VERSION ""

NS_ :

BS_:

BU_: Pegasus Marvel Laptop Stark Xavier stark Pegasus Marvel Laptop Stark Xavier stark Gtake

BO_ 1542 id606: 8 Stark
 SG_ Aux_battery_voltage : 15|16@0+ (0.01,0) [0|655.35] "V" Vector__XXX

BO_ 1801 id709: 8 Pegasus
 SG_ Fault_historic_details : 0|64@1+ (1,0) [0|255] "" Vector__XXX

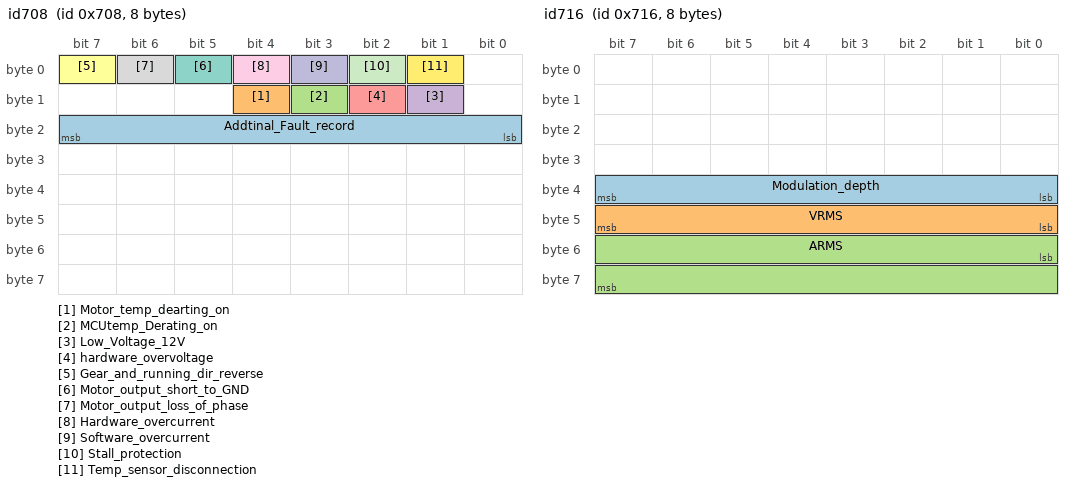
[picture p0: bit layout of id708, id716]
BO_ 1800 id708: 8 Pegasus
 SG_ Addtinal_Fault_record : 16|8@1+ (1,0) [0|255] "" Vector__XXX
 SG_ Motor_temp_dearting_on : 12|1@1+ (1,0) [0|1] "" Vector__XXX
 SG_ MCUtemp_Derating_on : 11|1@1+ (1,0) [0|1] "" Vector__XXX
 SG_ Low_Voltage_12V : 9|1@1+ (1,0) [0|1] "" Vector__XXX
 SG_ hardware_overvoltage : 10|1@1+ (1,0) [0|1] "" Vector__XXX
 SG_ Gear_and_running_dir_reverse : 7|1@1+ (1,0) [0|1] "" Vector__XXX
 SG_ Motor_output_short_to_GND : 5|1@1+ (1,0) [0|1] "" Vector__XXX
 SG_ Motor_output_loss_of_phase : 6|1@1+ (1,0) [0|1] "" Vector__XXX
 SG_ Hardware_overcurrent : 4|1@1+ (1,0) [0|1] "" Vector__XXX
 SG_ Software_overcurrent : 3|1@1+ (1,0) [0|1] "" Vector__XXX
 SG_ Stall_protection : 2|1@1+ (1,0) [0|1] "" Vector__XXX
 SG_ Temp_sensor_disconnection : 1|1@1+ (1,0) [0|1] "" Vector__XXX

BO_ 1828 id724: 8 Pegasus
 SG_ Motor_Torque_Estimated : 0|16@1- (0.1,0) [-3276.8|3276.7] "Nm" Vector__XXX

BO_ 1815 id717: 8 Pegasus
 SG_ Operating_frequency : 0|16@1- (1,0) [-32768|32767] "Hz" Vector__XXX

BO_ 1814 id716: 8 Pegasus
 SG_ Modulation_depth : 32|8@1+ (1,0) [0|0] "%" Vector__XXX
 SG_ VRMS : 40|8@1+ (1,0) [0|255] "V rms" Vector__XXX
 SG_ ARMS : 48|16@1+ (1,0) [0|65535] "A rms" Vector__XXX

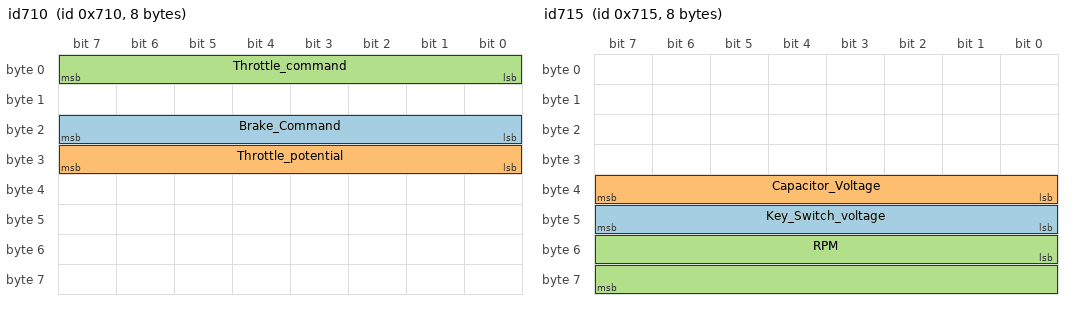
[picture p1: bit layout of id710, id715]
BO_ 1808 id710: 8 Pegasus
 SG_ Brake_Command : 16|8@1+ (1,0) [0|1] "" Vector__XXX
 SG_ Throttle_potential : 24|8@1+ (0.1,0) [0|25.5] "V" Vector__XXX
 SG_ Throttle_command : 0|8@1+ (1,0) [0|255] "%" Vector__XXX

BO_ 1813 id715: 8 Pegasus
 SG_ Key_Switch_voltage : 40|8@1+ (1,0) [0|24] "V" Vector__XXX
 SG_ Capacitor_Voltage : 32|8@1+ (1,0) [0|255] "V" Vector__XXX
 SG_ RPM : 48|16@1+ (1,0) [0|65535] "RPM" Vector__XXX

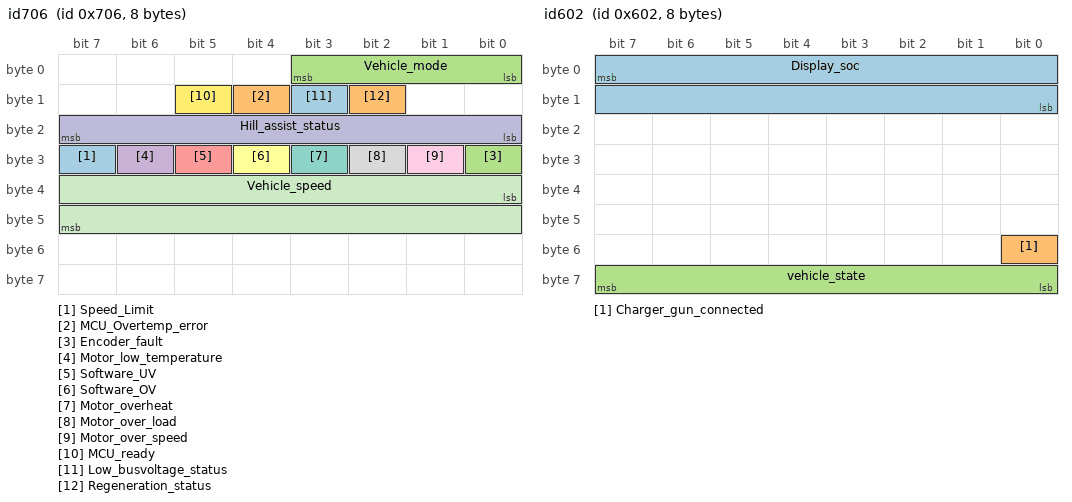
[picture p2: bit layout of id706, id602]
BO_ 1798 id706: 8 Pegasus
 SG_ Speed_Limit : 31|1@1+ (1,0) [0|1] "" Vector__XXX
 SG_ MCU_Overtemp_error : 12|1@1+ (1,0) [0|1] "" Vector__XXX
 SG_ Encoder_fault : 24|1@1+ (1,0) [0|1] "" Vector__XXX
 SG_ Motor_low_temperature : 30|1@1+ (1,0) [0|1] "" Vector__XXX
 SG_ Software_UV : 29|1@1+ (1,0) [0|1] "" Vector__XXX
 SG_ Software_OV : 28|1@1+ (1,0) [0|1] "" Vector__XXX
 SG_ Motor_overheat : 27|1@1+ (1,0) [0|1] "" Vector__XXX
 SG_ Motor_over_load : 26|1@1+ (1,0) [0|1] "" Vector__XXX
 SG_ Motor_over_speed : 25|1@1+ (1,0) [0|0] "" Vector__XXX
 SG_ Hill_assist_status : 16|8@1+ (1,0) [0|255] "" Vector__XXX
 SG_ Vehicle_speed : 32|16@1- (0.1,0) [-3276.8|3276.7] "Kmph" Vector__XXX
 SG_ MCU_ready : 13|1@1+ (1,0) [0|1] "" Vector__XXX
 SG_ Low_busvoltage_status : 11|1@1+ (1,0) [0|0] "" Vector__XXX
 SG_ Regeneration_status : 10|1@1+ (1,0) [0|1] "" Vector__XXX
 SG_ Vehicle_mode : 0|4@1+ (1,0) [0|15] "" Vector__XXX

BO_ 1797 id705: 8 Pegasus
 SG_ MCU_Temperature : 8|8@1+ (1,-50) [0|255] "C" Vector__XXX
 SG_ Motor_Temperature : 0|8@1+ (1,-50) [0|255] "C" Vector__XXX

BO_ 1025 id401: 8 Xavier
 SG_ Display_Speed : 0|8@1+ (1,0) [0|255] "Kmph" Vector__XXX

BO_ 1538 id602: 8 Stark
 SG_ Display_soc : 7|16@0+ (0.1,0) [0|0] "%" Vector__XXX
 SG_ Charger_gun_connected : 48|1@1+ (1,0) [0|2] "" Vector__XXX
 SG_ vehicle_state : 63|8@0+ (1,0) [0|10] "" Vector__XXX

BO_ 1539 id603: 8 Stark
 SG_ Odometer : 23|32@0+ (0.01,0) [0|429496729.5] "Km" Vector__XXX

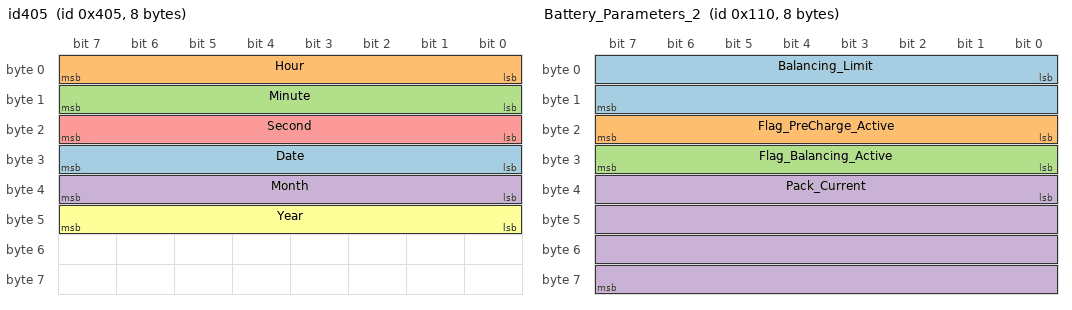
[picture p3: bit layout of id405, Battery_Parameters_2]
BO_ 1029 id405: 8 Xavier
 SG_ Date : 24|8@1+ (1,0) [0|0] "" Vector__XXX
 SG_ Hour : 0|8@1+ (1,0) [0|0] "" Vector__XXX
 SG_ Minute : 8|8@1+ (1,0) [0|0] "" Vector__XXX
 SG_ Month : 32|8@1+ (1,0) [0|0] "" Vector__XXX
 SG_ Second : 16|8@1+ (1,0) [0|0] "" Vector__XXX
 SG_ Year : 40|8@1+ (1,0) [0|0] "" Vector__XXX

BO_ 272 Battery_Parameters_2: 8 Vector__XXX
 SG_ Balancing_Limit : 0|16@1+ (0.1,0) [0|6553.5] "mV" Vector__XXX
 SG_ Flag_PreCharge_Active : 16|8@1+ (1,0) [0|255] "" Vector__XXX
 SG_ Flag_Balancing_Active : 24|8@1+ (1,0) [0|255] "" Vector__XXX
 SG_ Pack_Current : 32|32@1- (1E-05,0) [-21474.8|21474.8] "A" Vector__XXX

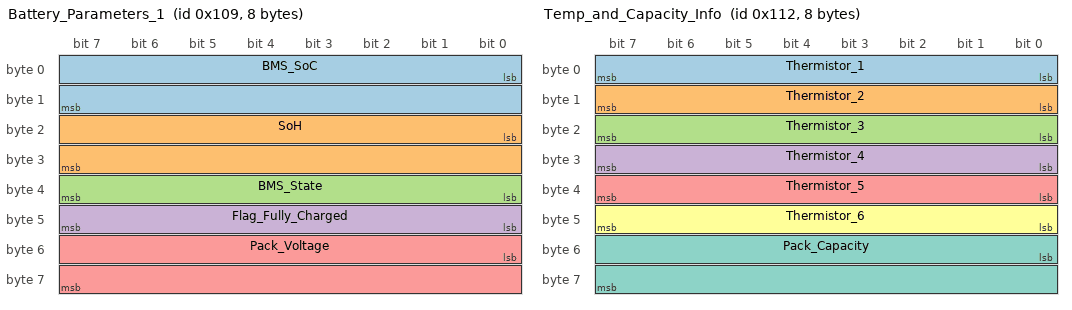
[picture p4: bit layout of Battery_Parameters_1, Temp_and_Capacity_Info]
BO_ 265 Battery_Parameters_1: 8 Vector__XXX
 SG_ BMS_SoC : 0|16@1+ (0.01,0) [0|655.35] "%" Vector__XXX
 SG_ SoH : 16|16@1+ (0.01,0) [0|655.35] "%" Vector__XXX
 SG_ BMS_State : 32|8@1+ (1,0) [0|255] "" Vector__XXX
 SG_ Flag_Fully_Charged : 40|8@1+ (1,0) [0|255] "" Vector__XXX
 SG_ Pack_Voltage : 48|16@1+ (0.1,0) [0|6553.5] "V" Vector__XXX

BO_ 274 Temp_and_Capacity_Info: 8 Vector__XXX
 SG_ Thermistor_1 : 0|8@1- (1,0) [-128|127] "degC" Vector__XXX
 SG_ Thermistor_2 : 8|8@1- (1,0) [-128|127] "degC" Vector__XXX
 SG_ Thermistor_3 : 16|8@1- (1,0) [-128|127] "degC" Vector__XXX
 SG_ Thermistor_4 : 24|8@1- (1,0) [-128|127] "degC" Vector__XXX
 SG_ Thermistor_5 : 32|8@1- (1,0) [-128|127] "degC" Vector__XXX
 SG_ Thermistor_6 : 40|8@1- (1,0) [-128|127] "degC" Vector__XXX
 SG_ Pack_Capacity : 48|16@1+ (0.01,0) [0|6553.5] "Ah" Vector__XXX

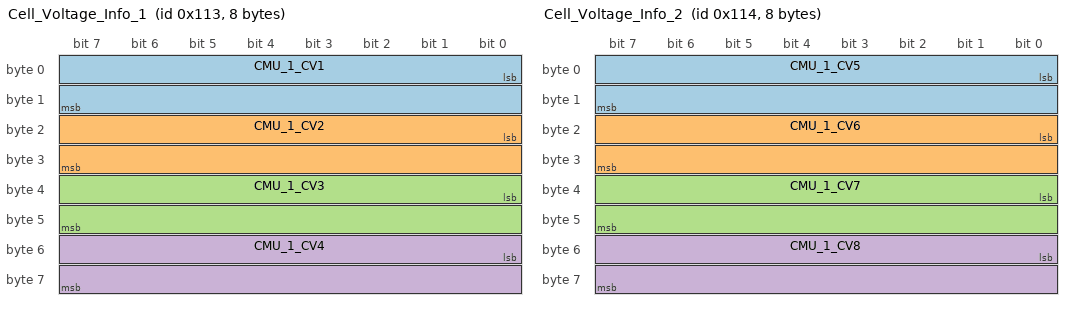
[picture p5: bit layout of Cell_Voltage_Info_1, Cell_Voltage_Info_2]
BO_ 275 Cell_Voltage_Info_1: 8 Vector__XXX
 SG_ CMU_1_CV1 : 0|16@1+ (0.1,0) [0|6553.5] "mV" Vector__XXX
 SG_ CMU_1_CV2 : 16|16@1+ (0.1,0) [0|6553.5] "mV" Vector__XXX
 SG_ CMU_1_CV3 : 32|16@1+ (0.1,0) [0|6553.5] "mV" Vector__XXX
 SG_ CMU_1_CV4 : 48|16@1+ (0.1,0) [0|6553.5] "mV" Vector__XXX

BO_ 276 Cell_Voltage_Info_2: 8 Vector__XXX
 SG_ CMU_1_CV5 : 0|16@1+ (0.1,0) [0|6553.5] "mV" Vector__XXX
 SG_ CMU_1_CV6 : 16|16@1+ (0.1,0) [0|6553.5] "mV" Vector__XXX
 SG_ CMU_1_CV7 : 32|16@1+ (0.1,0) [0|6553.5] "mV" Vector__XXX
 SG_ CMU_1_CV8 : 48|16@1+ (0.1,0) [0|6553.5] "mV" Vector__XXX

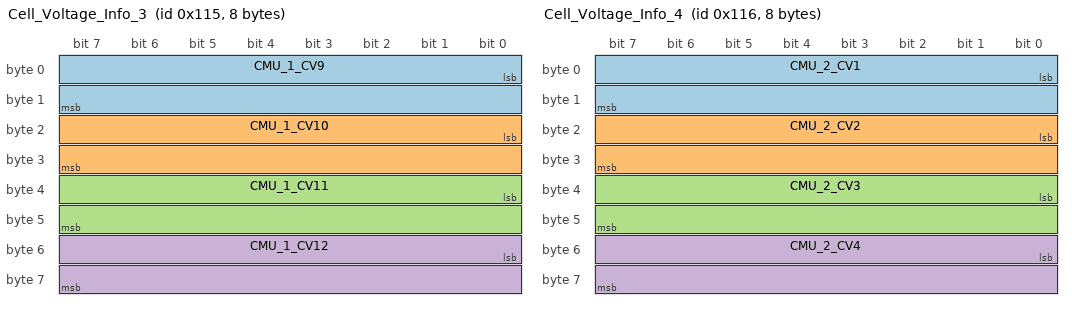
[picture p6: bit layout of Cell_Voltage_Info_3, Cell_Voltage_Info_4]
BO_ 277 Cell_Voltage_Info_3: 8 Vector__XXX
 SG_ CMU_1_CV9 : 0|16@1+ (0.1,0) [0|6553.5] "mV" Vector__XXX
 SG_ CMU_1_CV10 : 16|16@1+ (0.1,0) [0|6553.5] "mV" Vector__XXX
 SG_ CMU_1_CV11 : 32|16@1+ (0.1,0) [0|6553.5] "mV" Vector__XXX
 SG_ CMU_1_CV12 : 48|16@1+ (0.1,0) [0|6553.5] "mV" Vector__XXX

BO_ 278 Cell_Voltage_Info_4: 8 Vector__XXX
 SG_ CMU_2_CV1 : 0|16@1+ (0.1,0) [0|6553.5] "mV" Vector__XXX
 SG_ CMU_2_CV2 : 16|16@1+ (0.1,0) [0|6553.5] "mV" Vector__XXX
 SG_ CMU_2_CV3 : 32|16@1+ (0.1,0) [0|6553.5] "mV" Vector__XXX
 SG_ CMU_2_CV4 : 48|16@1+ (0.1,0) [0|6553.5] "mV" Vector__XXX

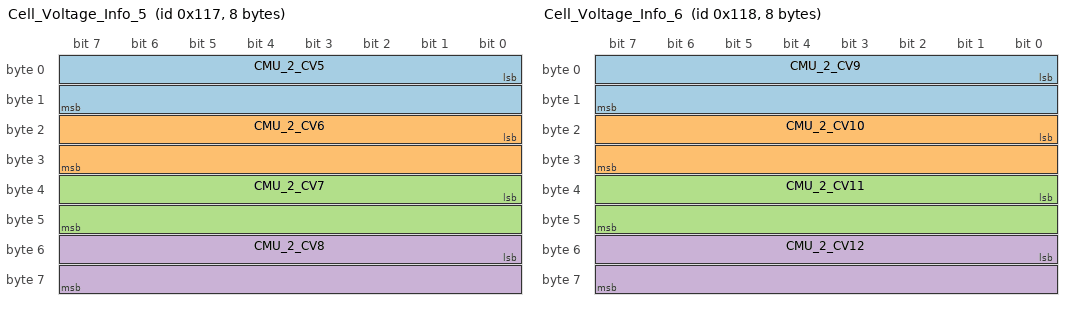
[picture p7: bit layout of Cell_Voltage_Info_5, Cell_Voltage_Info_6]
BO_ 279 Cell_Voltage_Info_5: 8 Vector__XXX
 SG_ CMU_2_CV5 : 0|16@1+ (0.1,0) [0|6553.5] "mV" Vector__XXX
 SG_ CMU_2_CV6 : 16|16@1+ (0.1,0) [0|6553.5] "mV" Vector__XXX
 SG_ CMU_2_CV7 : 32|16@1+ (0.1,0) [0|6553.5] "mV" Vector__XXX
 SG_ CMU_2_CV8 : 48|16@1+ (0.1,0) [0|6553.5] "mV" Vector__XXX

BO_ 280 Cell_Voltage_Info_6: 8 Vector__XXX
 SG_ CMU_2_CV9 : 0|16@1+ (0.1,0) [0|6553.5] "mV" Vector__XXX
 SG_ CMU_2_CV10 : 16|16@1+ (0.1,0) [0|6553.5] "mV" Vector__XXX
 SG_ CMU_2_CV11 : 32|16@1+ (0.1,0) [0|6553.5] "mV" Vector__XXX
 SG_ CMU_2_CV12 : 48|16@1+ (0.1,0) [0|6553.5] "mV" Vector__XXX

BO_ 263 Charger_Info: 8 Vector__XXX
 SG_ Flag_Fully_Charged : 40|1@0+ (1,0) [0|1] "" Vector__XXX

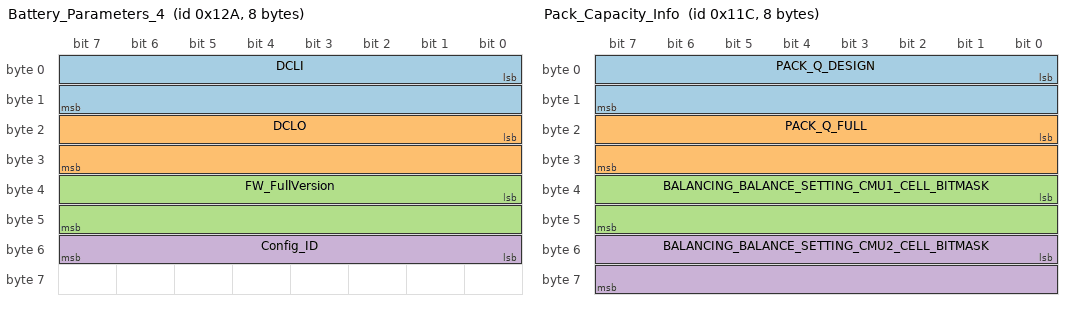
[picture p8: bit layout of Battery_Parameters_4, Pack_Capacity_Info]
BO_ 298 Battery_Parameters_4: 8 Vector__XXX
 SG_ DCLI : 0|16@1+ (0.1,0) [0|6553.5] "A" Vector__XXX
 SG_ DCLO : 16|16@1+ (0.1,0) [0|6553.5] "A" Vector__XXX
 SG_ FW_FullVersion : 32|16@1+ (1,0) [0|65535] "" Vector__XXX
 SG_ Config_ID : 48|8@1+ (1,0) [0|255] "" Vector__XXX

BO_ 266 Battery_Parameters_6: 8 Vector__XXX
 SG_ PACK_RESISTANCE_U : 0|32@1+ (0.1,0) [0|6553.5] "mohm" Vector__XXX

BO_ 284 Pack_Capacity_Info: 8 Vector__XXX
 SG_ PACK_Q_DESIGN : 0|16@1+ (0.1,0) [0|6553.5] "Ah" Vector__XXX
 SG_ PACK_Q_FULL : 16|16@1+ (0.1,0) [0|6553.5] "Ah" Vector__XXX
 SG_ BALANCING_BALANCE_SETTING_CMU1_CELL_BITMASK : 32|16@1+ (0.1,0) [0|6553.5] "mV" Vector__XXX
 SG_ BALANCING_BALANCE_SETTING_CMU2_CELL_BITMASK : 48|16@1+ (0.1,0) [0|6553.5] "mV" Vector__XXX

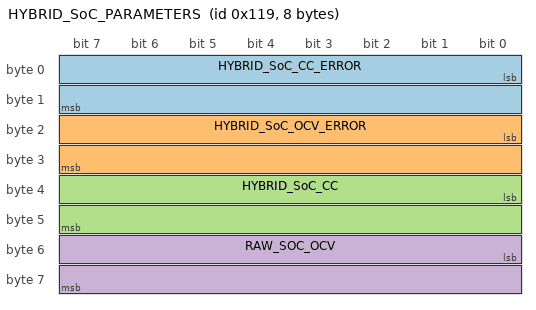
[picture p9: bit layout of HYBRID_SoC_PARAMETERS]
BO_ 281 HYBRID_SoC_PARAMETERS: 8 Vector__XXX
 SG_ HYBRID_SoC_CC_ERROR : 0|16@1+ (0.1,0) [0|6553.5] "%" Vector__XXX
 SG_ HYBRID_SoC_OCV_ERROR : 16|16@1+ (0.1,0) [0|6553.5] "%" Vector__XXX
 SG_ HYBRID_SoC_CC : 32|16@1+ (1,0) [0|65535] "%" Vector__XXX
 SG_ RAW_SOC_OCV : 48|16@1+ (1,0) [0|65535] "%" Vector__XXX

BO_ 288 TX16: 8 Vector__XXX
 SG_ SOC_INTERNAL : 0|16@1+ (0.01,0) [0|655.35] "%" Vector__XXX
 SG_ PACK_CYCLE_NUMBER : 16|16@1+ (1,0) [0|65535] "" Vector__XXX

BO_ 267 TX17: 8 Vector__XXX
 SG_ TOTAL_DISCHARGE_AH : 32|32@1+ (0.1,0) [0|429496729.5] "Ah" Vector__XXX

BO_ 268 TX18: 8 Vector__XXX
 SG_ SOE_WS : 0|32@1+ (1,0) [0|-1] "Ws" Vector__XXX
 SG_ SOE_FULL_WS : 32|32@1+ (1,0) [0|-1] "Ws" Vector__XXX

BO_ 269 TX19: 8 Vector__XXX
 SG_ P_TOTAL_CHARGE_WH : 0|32@1+ (0.1,0) [0|429496729.5] "Wh" Vector__XXX
 SG_ P_TOTAL_DISCHARGE_WH : 32|32@1+ (0.1,0) [0|429496729.5] "Wh" Vector__XXX

BO_ 600 Active_Error: 8 Vector__XXX
 SG_ Active_error_Count : 40|16@1+ (1,0) [0|65535] "" Vector__XXX

BO_ 602 Error_Code_1: 8 Vector__XXX
 SG_ Error_Code_1 : 55|16@0+ (1,0) [0|65535] "" Vector__XXX

BO_ 603 Error_Code_2: 8 Vector__XXX
 SG_ Error_Code_2 : 55|16@0+ (1,0) [0|65535] "" Vector__XXX

BO_ 604 Error_Code_3: 8 Vector__XXX
 SG_ Error_Code_3 : 55|16@0+ (1,0) [0|65535] "" Vector__XXX

BO_ 605 Error_Code_4: 8 Vector__XXX
 SG_ Error_Code_4 : 55|16@0+ (1,0) [0|65535] "" Vector__XXX

BO_ 606 Error_Code_5: 8 Vector__XXX
 SG_ Error_Code_5 : 55|16@0+ (1,0) [0|65535] "" Vector__XXX

BA_DEF_ SG_  "SigType" ENUM  "Default","Range","RangeSigned","ASCII","Discrete","Control","ReferencePGN","DTC","StringDelimiter","StringLength","StringLengthControl","MessageCounter","MessageChecksum";
BA_DEF_ SG_  "GenSigSendType" ENUM  "Cyclic","OnWrite","OnWriteWithRepetition","OnChange","OnChangeWithRepetition","IfActive","IfActiveWithRepetition","NoSigSendType";
BA_DEF_ SG_  "GenSigStartValue" INT 0 2147483647;
BA_DEF_ BO_  "GenMsgSendType" ENUM  "cyclic","NotUsed","IfActive","NotUsed","NotUsed","NotUsed","NotUsed","NotUsed","noMsgSendType";
BA_DEF_  "DBName" STRING ;
BA_DEF_ BO_  "VFrameFormat" ENUM  "StandardCAN","ExtendedCAN","reserved","J1939PG";
BA_DEF_ SG_  "SigType" ENUM  "Default","Range","RangeSigned","ASCII","Discrete","Control","ReferencePGN","DTC","StringDelimiter","StringLength","StringLengthControl","MessageCounter","MessageChecksum";
BA_DEF_ SG_  "GenSigSendType" ENUM  "Cyclic","OnWrite","OnWriteWithRepetition","OnChange","OnChangeWithRepetition","IfActive","IfActiveWithRepetition","NoSigSendType";
BA_DEF_ SG_  "GenSigStartValue" INT 0 2147483647;
BA_DEF_ BO_  "GenMsgSendType" ENUM  "cyclic","NotUsed","IfActive","NotUsed","NotUsed","NotUsed","NotUsed","NotUsed","noMsgSendType";
BA_DEF_  "DBName" STRING ;
BA_DEF_ BO_  "VFrameFormat" ENUM  "StandardCAN","ExtendedCAN","reserved","J1939PG";
BA_DEF_ SG_  "SigType" ENUM  "Default","Range","RangeSigned","ASCII","Discrete","Control","ReferencePGN","DTC","StringDelimiter","StringLength","StringLengthControl","MessageCounter","MessageChecksum";
BA_DEF_ SG_  "GenSigSendType" ENUM  "Cyclic","OnWrite","OnWriteWithRepetition","OnChange","OnChangeWithRepetition","IfActive","IfActiveWithRepetition","NoSigSendType";
BA_DEF_ SG_  "GenSigStartValue" INT 0 2147483647;
BA_DEF_ BO_  "GenMsgSendType" ENUM  "cyclic","NotUsed","IfActive","NotUsed","NotUsed","NotUsed","NotUsed","NotUsed","noMsgSendType";
BA_DEF_  "DBName" STRING ;
BA_DEF_ BO_  "VFrameFormat" ENUM  "StandardCAN","ExtendedCAN","reserved","J1939PG";
BA_DEF_DEF_  "SigType" "Default";
BA_DEF_DEF_  "GenSigSendType" "Cyclic";
BA_DEF_DEF_  "GenSigStartValue" 0;
BA_DEF_DEF_  "GenMsgSendType" "cyclic";
BA_DEF_DEF_  "DBName" "";
BA_DEF_DEF_  "VFrameFormat" "StandardCAN";
BA_DEF_DEF_  "SigType" "Default";
BA_DEF_DEF_  "GenSigSendType" "Cyclic";
BA_DEF_DEF_  "GenSigStartValue" 0;
BA_DEF_DEF_  "GenMsgSendType" "cyclic";
BA_DEF_DEF_  "DBName" "";
BA_DEF_DEF_  "VFrameFormat" "StandardCAN";
BA_DEF_DEF_  "SigType" "Default";
BA_DEF_DEF_  "GenSigSendType" "Cyclic";
BA_DEF_DEF_  "GenSigStartValue" 0;
BA_DEF_DEF_  "GenMsgSendType" "cyclic";
BA_DEF_DEF_  "DBName" "";
BA_DEF_DEF_  "VFrameFormat" "StandardCAN";
BA_ "DBName" "D03CAN";
BA_ "DBName" "D03CAN";
BA_ "DBName" "D03CAN";
BA_ "GenSigStartValue" SG_ 1797 MCU_Temperature 50;
BA_ "GenSigStartValue" SG_ 1797 MCU_Temperature 50;
BA_ "GenSigStartValue" SG_ 1797 Motor_Temperature 50;
BA_ "GenSigStartValue" SG_ 1797 Motor_Temperature 50;
VAL_ 1800 Motor_temp_dearting_on 1 "1" 0 "0" ;
VAL_ 1800 MCUtemp_Derating_on 1 "1" 0 "0" ;
VAL_ 1800 Low_Voltage_12V 1 "1" 0 "0" ;
VAL_ 1800 Gear_and_running_dir_reverse 1 "1" 0 "0" ;
VAL_ 1800 Motor_output_short_to_GND 1 "1" 0 "0" ;
VAL_ 1800 Motor_output_loss_of_phase 1 "1" 0 "0" ;
VAL_ 1800 Hardware_overcurrent 1 "1" 0 "0" ;
VAL_ 1800 Software_overcurrent 1 "1" 0 "0" ;
VAL_ 1800 Stall_protection 1 "1" 0 "0" ;
VAL_ 1800 Temp_sensor_disconnection 1 "1" 0 "0" ;
VAL_ 1808 Brake_Command 1 "1" 0 "0" ;
VAL_ 1798 Speed_Limit 1 "1" 0 "0" ;
VAL_ 1798 MCU_Overtemp_error 1 "1" 0 "0" ;
VAL_ 1798 Encoder_fault 1 "1" 0 "0" ;
VAL_ 1798 Motor_low_temperature 1 "1" 0 "0" ;
VAL_ 1798 Software_UV 1 "1" 0 "0" ;
VAL_ 1798 Software_OV 1 "1" 0 "0" ;
VAL_ 1798 Motor_overheat 1 "1" 0 "0" ;
VAL_ 1798 Motor_over_load 1 "1" 0 "0" ;
VAL_ 1798 Motor_over_speed 1 "1" 0 "0" ;
VAL_ 1798 MCU_ready 1 "1" 0 "0" ;
VAL_ 1798 Low_busvoltage_status 1 "1" 0 "0" ;
VAL_ 1798 Regeneration_status 1 "1" 0 "0" ;
VAL_ 1798 Vehicle_mode 8 "Thunder" 4 "Reverse" 2 "Eco" 1 "Neutral" ;
VAL_ 602 Error_Code_1 2 "ERROR_GENERAL_IOB" 6 "ERROR_GENERAL_NULLPOINT" 7 "ERROR_GENERAL_PAOB" 306 "ERROR_CAN_RX_TIMEOUT" 701 "ERROR_INVALID_TIME_FROM_RTC" 1011 "ERROR_CELL_VDELTA" 1012 "ERROR_CELL_TDELTA" 1100 "ERROR_TEMP_AUX_NO_VALUE" 1116 "ERROR_TEMP_AUX_SHORTED" 1132 "ERROR_TEMP_AUX_OPEN" 1148 "ERROR_TEMP_AUX_MIN_CH01" 1149 "ERROR_TEMP_AUX_MIN_CH02" 1150 "ERROR_TEMP_AUX_MIN_CH03" 1151 "ERROR_TEMP_AUX_MIN_CH04" 1152 "ERROR_TEMP_AUX_MIN_CH05" 1153 "ERROR_TEMP_AUX_MIN_CH06" 1154 "ERROR_TEMP_AUX_MIN_CH07" 1165 "ERROR_TEMP_AUX_MAX_CH01" 1166 "ERROR_TEMP_AUX_MAX_CH02" 1167 "ERROR_TEMP_AUX_MAX_CH03" 1168 "ERROR_TEMP_AUX_MAX_CH04" 1169 "ERROR_TEMP_AUX_MAX_CH05" 1170 "ERROR_TEMP_AUX_MAX_CH06" 1171 "ERROR_TEMP_AUX_MAX_CH08" 2000 "ERROR_SYS_LIM_CELL_V_MIN" 2001 "ERROR_SYS_LIM_CELL_V_MAX" 2004 "ERROR_SYS_LIM_CELL_T_MIN" 2005 "ERROR_SYS_LIM_CELL_T_MAX" 2008 "ERROR_SYS_LIM_PACK_I_IN" 2009 "ERROR_SYS_LIM_PACK_I_OUT" 2010 "ERROR_SYS_LIM_PACK_I_2T" 2011 "ERROR_SYS_CELL_V_NO_VALUE" 2012 "ERROR_SYS_CELL_T_NO_VALUE" 2013 "EROR_SYS_CELL_T_SHORTED" 2014 "ERROR_SYS_CELL_T_OPEN" 2015 "ERROR_SYS_CMU_PCB_T_NO_VALUE" 2016 "ERROR_SYS_CMU_PCB_T_SHORTED" 2017 "ERROR_SYS_CMU_PCB_T_OPEN" 2021 "ERROR_SYS_FB_LOAD_NEG_MISSING" 2022 "ERROR_SYS_FB_LOAD_POS_MISSING" 2023 "ERROR_SYS_FB_PRE_CHARGE_MISSING" 2024 "ERROR_SYS_FB_CHG_NEG_MISSING" 2025 "ERROR_SYS_FB_LOAD_NEG_WELDED" 2026 "ERROR_SYS_FB_LOAD_POS_WELDED" 2027 "ERROR_SYS_FB_PRE_CHARGE_WELDED" 2028 "ERROR_SYS_FB_CHG_NEG_WELDED" 2031 "ERROR_SYS_CONTACTOR_RETRIES" 2042 "ERROR_SYS_LIM_CHG_I_OVER_UNDER" 2048 "ERROR_SYS_OPEN_WIRE" 2050 "ERROR_SYS_ESTOP" 2051 "CONTACTOR_PRE_CHARGE_OPEN" 2052 "CONTACTOR_PRE_CHARGE_SHORT" 2053 "CONTACTOR_POS_OPEN" 2054 "CONTACTOR_SHORT" 2055 "CONTACTOR_PRE_CHARGE_TIMEOUT" 2056 "RESISTANCE_TOO_HIGH" 2057 "DUPLICATE_NODE_ID" 2058 "MISCHARGE" 2059 "MISLOAD" 2062 "CHARGE_NO_RESPONSE" 2063 "ERROR_READY_CURRENT_HIGH" 2080 "AFE_MEASUREMENT_ERROR" 2081 "ERROR_AFE_SM" ;
VAL_ 603 Error_Code_2 2 "ERROR_GENERAL_IOB" 6 "ERROR_GENERAL_NULLPOINT" 7 "ERROR_GENERAL_PAOB" 306 "ERROR_CAN_RX_TIMEOUT" 701 "ERROR_INVALID_TIME_FROM_RTC" 1011 "ERROR_CELL_VDELTA" 1012 "ERROR_CELL_TDELTA" 1100 "ERROR_TEMP_AUX_NO_VALUE" 1116 "ERROR_TEMP_AUX_SHORTED" 1132 "ERROR_TEMP_AUX_OPEN" 1148 "ERROR_TEMP_AUX_MIN_CH01" 1149 "ERROR_TEMP_AUX_MIN_CH02" 1150 "ERROR_TEMP_AUX_MIN_CH03" 1151 "ERROR_TEMP_AUX_MIN_CH04" 1152 "ERROR_TEMP_AUX_MIN_CH05" 1153 "ERROR_TEMP_AUX_MIN_CH06" 1154 "ERROR_TEMP_AUX_MIN_CH07" 1165 "ERROR_TEMP_AUX_MAX_CH01" 1166 "ERROR_TEMP_AUX_MAX_CH02" 1167 "ERROR_TEMP_AUX_MAX_CH03" 1168 "ERROR_TEMP_AUX_MAX_CH04" 1169 "ERROR_TEMP_AUX_MAX_CH05" 1170 "ERROR_TEMP_AUX_MAX_CH06" 1171 "ERROR_TEMP_AUX_MAX_CH08" 2000 "ERROR_SYS_LIM_CELL_V_MIN" 2001 "ERROR_SYS_LIM_CELL_V_MAX" 2004 "ERROR_SYS_LIM_CELL_T_MIN" 2005 "ERROR_SYS_LIM_CELL_T_MAX" 2008 "ERROR_SYS_LIM_PACK_I_IN" 2009 "ERROR_SYS_LIM_PACK_I_OUT" 2010 "ERROR_SYS_LIM_PACK_I_2T" 2011 "ERROR_SYS_CELL_V_NO_VALUE" 2012 "ERROR_SYS_CELL_T_NO_VALUE" 2013 "EROR_SYS_CELL_T_SHORTED" 2014 "ERROR_SYS_CELL_T_OPEN" 2015 "ERROR_SYS_CMU_PCB_T_NO_VALUE" 2016 "ERROR_SYS_CMU_PCB_T_SHORTED" 2017 "ERROR_SYS_CMU_PCB_T_OPEN" 2021 "ERROR_SYS_FB_LOAD_NEG_MISSING" 2022 "ERROR_SYS_FB_LOAD_POS_MISSING" 2023 "ERROR_SYS_FB_PRE_CHARGE_MISSING" 2024 "ERROR_SYS_FB_CHG_NEG_MISSING" 2025 "ERROR_SYS_FB_LOAD_NEG_WELDED" 2026 "ERROR_SYS_FB_LOAD_POS_WELDED" 2027 "ERROR_SYS_FB_PRE_CHARGE_WELDED" 2028 "ERROR_SYS_FB_CHG_NEG_WELDED" 2031 "ERROR_SYS_CONTACTOR_RETRIES" 2042 "ERROR_SYS_LIM_CHG_I_OVER_UNDER" 2048 "ERROR_SYS_OPEN_WIRE" 2050 "ERROR_SYS_ESTOP" 2051 "CONTACTOR_PRE_CHARGE_OPEN" 2052 "CONTACTOR_PRE_CHARGE_SHORT" 2053 "CONTACTOR_POS_OPEN" 2054 "CONTACTOR_SHORT" 2055 "CONTACTOR_PRE_CHARGE_TIMEOUT" 2056 "RESISTANCE_TOO_HIGH" 2057 "DUPLICATE_NODE_ID" 2058 "MISCHARGE" 2059 "MISLOAD" 2062 "CHARGE_NO_RESPONSE" 2063 "ERROR_READY_CURRENT_HIGH" 2080 "AFE_MEASUREMENT_ERROR" 2081 "ERROR_AFE_SM" ;
VAL_ 604 Error_Code_3 2 "ERROR_GENERAL_IOB" 6 "ERROR_GENERAL_NULLPOINT" 7 "ERROR_GENERAL_PAOB" 306 "ERROR_CAN_RX_TIMEOUT" 701 "ERROR_INVALID_TIME_FROM_RTC" 1011 "ERROR_CELL_VDELTA" 1012 "ERROR_CELL_TDELTA" 1100 "ERROR_TEMP_AUX_NO_VALUE" 1116 "ERROR_TEMP_AUX_SHORTED" 1132 "ERROR_TEMP_AUX_OPEN" 1148 "ERROR_TEMP_AUX_MIN_CH01" 1149 "ERROR_TEMP_AUX_MIN_CH02" 1150 "ERROR_TEMP_AUX_MIN_CH03" 1151 "ERROR_TEMP_AUX_MIN_CH04" 1152 "ERROR_TEMP_AUX_MIN_CH05" 1153 "ERROR_TEMP_AUX_MIN_CH06" 1154 "ERROR_TEMP_AUX_MIN_CH07" 1165 "ERROR_TEMP_AUX_MAX_CH01" 1166 "ERROR_TEMP_AUX_MAX_CH02" 1167 "ERROR_TEMP_AUX_MAX_CH03" 1168 "ERROR_TEMP_AUX_MAX_CH04" 1169 "ERROR_TEMP_AUX_MAX_CH05" 1170 "ERROR_TEMP_AUX_MAX_CH06" 1171 "ERROR_TEMP_AUX_MAX_CH08" 2000 "ERROR_SYS_LIM_CELL_V_MIN" 2001 "ERROR_SYS_LIM_CELL_V_MAX" 2004 "ERROR_SYS_LIM_CELL_T_MIN" 2005 "ERROR_SYS_LIM_CELL_T_MAX" 2008 "ERROR_SYS_LIM_PACK_I_IN" 2009 "ERROR_SYS_LIM_PACK_I_OUT" 2010 "ERROR_SYS_LIM_PACK_I_2T" 2011 "ERROR_SYS_CELL_V_NO_VALUE" 2012 "ERROR_SYS_CELL_T_NO_VALUE" 2013 "EROR_SYS_CELL_T_SHORTED" 2014 "ERROR_SYS_CELL_T_OPEN" 2015 "ERROR_SYS_CMU_PCB_T_NO_VALUE" 2016 "ERROR_SYS_CMU_PCB_T_SHORTED" 2017 "ERROR_SYS_CMU_PCB_T_OPEN" 2021 "ERROR_SYS_FB_LOAD_NEG_MISSING" 2022 "ERROR_SYS_FB_LOAD_POS_MISSING" 2023 "ERROR_SYS_FB_PRE_CHARGE_MISSING" 2024 "ERROR_SYS_FB_CHG_NEG_MISSING" 2025 "ERROR_SYS_FB_LOAD_NEG_WELDED" 2026 "ERROR_SYS_FB_LOAD_POS_WELDED" 2027 "ERROR_SYS_FB_PRE_CHARGE_WELDED" 2028 "ERROR_SYS_FB_CHG_NEG_WELDED" 2031 "ERROR_SYS_CONTACTOR_RETRIES" 2042 "ERROR_SYS_LIM_CHG_I_OVER_UNDER" 2048 "ERROR_SYS_OPEN_WIRE" 2050 "ERROR_SYS_ESTOP" 2051 "CONTACTOR_PRE_CHARGE_OPEN" 2052 "CONTACTOR_PRE_CHARGE_SHORT" 2053 "CONTACTOR_POS_OPEN" 2054 "CONTACTOR_SHORT" 2055 "CONTACTOR_PRE_CHARGE_TIMEOUT" 2056 "RESISTANCE_TOO_HIGH" 2057 "DUPLICATE_NODE_ID" 2058 "MISCHARGE" 2059 "MISLOAD" 2062 "CHARGE_NO_RESPONSE" 2063 "ERROR_READY_CURRENT_HIGH" 2080 "AFE_MEASUREMENT_ERROR" 2081 "ERROR_AFE_SM" ;
VAL_ 605 Error_Code_4 2 "ERROR_GENERAL_IOB" 6 "ERROR_GENERAL_NULLPOINT" 7 "ERROR_GENERAL_PAOB" 306 "ERROR_CAN_RX_TIMEOUT" 701 "ERROR_INVALID_TIME_FROM_RTC" 1011 "ERROR_CELL_VDELTA" 1012 "ERROR_CELL_TDELTA" 1100 "ERROR_TEMP_AUX_NO_VALUE" 1116 "ERROR_TEMP_AUX_SHORTED" 1132 "ERROR_TEMP_AUX_OPEN" 1148 "ERROR_TEMP_AUX_MIN_CH01" 1149 "ERROR_TEMP_AUX_MIN_CH02" 1150 "ERROR_TEMP_AUX_MIN_CH03" 1151 "ERROR_TEMP_AUX_MIN_CH04" 1152 "ERROR_TEMP_AUX_MIN_CH05" 1153 "ERROR_TEMP_AUX_MIN_CH06" 1154 "ERROR_TEMP_AUX_MIN_CH07" 1165 "ERROR_TEMP_AUX_MAX_CH01" 1166 "ERROR_TEMP_AUX_MAX_CH02" 1167 "ERROR_TEMP_AUX_MAX_CH03" 1168 "ERROR_TEMP_AUX_MAX_CH04" 1169 "ERROR_TEMP_AUX_MAX_CH05" 1170 "ERROR_TEMP_AUX_MAX_CH06" 1171 "ERROR_TEMP_AUX_MAX_CH08" 2000 "ERROR_SYS_LIM_CELL_V_MIN" 2001 "ERROR_SYS_LIM_CELL_V_MAX" 2004 "ERROR_SYS_LIM_CELL_T_MIN" 2005 "ERROR_SYS_LIM_CELL_T_MAX" 2008 "ERROR_SYS_LIM_PACK_I_IN" 2009 "ERROR_SYS_LIM_PACK_I_OUT" 2010 "ERROR_SYS_LIM_PACK_I_2T" 2011 "ERROR_SYS_CELL_V_NO_VALUE" 2012 "ERROR_SYS_CELL_T_NO_VALUE" 2013 "EROR_SYS_CELL_T_SHORTED" 2014 "ERROR_SYS_CELL_T_OPEN" 2015 "ERROR_SYS_CMU_PCB_T_NO_VALUE" 2016 "ERROR_SYS_CMU_PCB_T_SHORTED" 2017 "ERROR_SYS_CMU_PCB_T_OPEN" 2021 "ERROR_SYS_FB_LOAD_NEG_MISSING" 2022 "ERROR_SYS_FB_LOAD_POS_MISSING" 2023 "ERROR_SYS_FB_PRE_CHARGE_MISSING" 2024 "ERROR_SYS_FB_CHG_NEG_MISSING" 2025 "ERROR_SYS_FB_LOAD_NEG_WELDED" 2026 "ERROR_SYS_FB_LOAD_POS_WELDED" 2027 "ERROR_SYS_FB_PRE_CHARGE_WELDED" 2028 "ERROR_SYS_FB_CHG_NEG_WELDED" 2031 "ERROR_SYS_CONTACTOR_RETRIES" 2042 "ERROR_SYS_LIM_CHG_I_OVER_UNDER" 2048 "ERROR_SYS_OPEN_WIRE" 2050 "ERROR_SYS_ESTOP" 2051 "CONTACTOR_PRE_CHARGE_OPEN" 2052 "CONTACTOR_PRE_CHARGE_SHORT" 2053 "CONTACTOR_POS_OPEN" 2054 "CONTACTOR_SHORT" 2055 "CONTACTOR_PRE_CHARGE_TIMEOUT" 2056 "RESISTANCE_TOO_HIGH" 2057 "DUPLICATE_NODE_ID" 2058 "MISCHARGE" 2059 "MISLOAD" 2062 "CHARGE_NO_RESPONSE" 2063 "ERROR_READY_CURRENT_HIGH" 2080 "AFE_MEASUREMENT_ERROR" 2081 "ERROR_AFE_SM" ;
VAL_ 606 Error_Code_5 2 "ERROR_GENERAL_IOB" 6 "ERROR_GENERAL_NULLPOINT" 7 "ERROR_GENERAL_PAOB" 306 "ERROR_CAN_RX_TIMEOUT" 701 "ERROR_INVALID_TIME_FROM_RTC" 1011 "ERROR_CELL_VDELTA" 1012 "ERROR_CELL_TDELTA" 1100 "ERROR_TEMP_AUX_NO_VALUE" 1116 "ERROR_TEMP_AUX_SHORTED" 1132 "ERROR_TEMP_AUX_OPEN" 1148 "ERROR_TEMP_AUX_MIN_CH01" 1149 "ERROR_TEMP_AUX_MIN_CH02" 1150 "ERROR_TEMP_AUX_MIN_CH03" 1151 "ERROR_TEMP_AUX_MIN_CH04" 1152 "ERROR_TEMP_AUX_MIN_CH05" 1153 "ERROR_TEMP_AUX_MIN_CH06" 1154 "ERROR_TEMP_AUX_MIN_CH07" 1165 "ERROR_TEMP_AUX_MAX_CH01" 1166 "ERROR_TEMP_AUX_MAX_CH02" 1167 "ERROR_TEMP_AUX_MAX_CH03" 1168 "ERROR_TEMP_AUX_MAX_CH04" 1169 "ERROR_TEMP_AUX_MAX_CH05" 1170 "ERROR_TEMP_AUX_MAX_CH06" 1171 "ERROR_TEMP_AUX_MAX_CH08" 2000 "ERROR_SYS_LIM_CELL_V_MIN" 2001 "ERROR_SYS_LIM_CELL_V_MAX" 2004 "ERROR_SYS_LIM_CELL_T_MIN" 2005 "ERROR_SYS_LIM_CELL_T_MAX" 2008 "ERROR_SYS_LIM_PACK_I_IN" 2009 "ERROR_SYS_LIM_PACK_I_OUT" 2010 "ERROR_SYS_LIM_PACK_I_2T" 2011 "ERROR_SYS_CELL_V_NO_VALUE" 2012 "ERROR_SYS_CELL_T_NO_VALUE" 2013 "EROR_SYS_CELL_T_SHORTED" 2014 "ERROR_SYS_CELL_T_OPEN" 2015 "ERROR_SYS_CMU_PCB_T_NO_VALUE" 2016 "ERROR_SYS_CMU_PCB_T_SHORTED" 2017 "ERROR_SYS_CMU_PCB_T_OPEN" 2021 "ERROR_SYS_FB_LOAD_NEG_MISSING" 2022 "ERROR_SYS_FB_LOAD_POS_MISSING" 2023 "ERROR_SYS_FB_PRE_CHARGE_MISSING" 2024 "ERROR_SYS_FB_CHG_NEG_MISSING" 2025 "ERROR_SYS_FB_LOAD_NEG_WELDED" 2026 "ERROR_SYS_FB_LOAD_POS_WELDED" 2027 "ERROR_SYS_FB_PRE_CHARGE_WELDED" 2028 "ERROR_SYS_FB_CHG_NEG_WELDED" 2031 "ERROR_SYS_CONTACTOR_RETRIES" 2042 "ERROR_SYS_LIM_CHG_I_OVER_UNDER" 2048 "ERROR_SYS_OPEN_WIRE" 2050 "ERROR_SYS_ESTOP" 2051 "CONTACTOR_PRE_CHARGE_OPEN" 2052 "CONTACTOR_PRE_CHARGE_SHORT" 2053 "CONTACTOR_POS_OPEN" 2054 "CONTACTOR_SHORT" 2055 "CONTACTOR_PRE_CHARGE_TIMEOUT" 2056 "RESISTANCE_TOO_HIGH" 2057 "DUPLICATE_NODE_ID" 2058 "MISCHARGE" 2059 "MISLOAD" 2062 "CHARGE_NO_RESPONSE" 2063 "ERROR_READY_CURRENT_HIGH" 2080 "AFE_MEASUREMENT_ERROR" 2081 "ERROR_AFE_SM" ;
